VERSION ""

NS_ :

BS_:

BU_: Vector__XXX

BA_DEF_ BO_  "VFrameFormat" ENUM  "StandardCAN","ExtendedCAN";
BA_DEF_DEF_ "VFrameFormat" "StandardCAN";

CM_ "Ioniq 6 frame ids. The CCU CAN hub, which replaced the older ICU CAN hub, re-addresses classic 11-bit car-bus frames onto 29-bit extended ids that encode the original 11-bit id. This predates ccNC head units and is NOT a ccNC feature:";
CM_ "    prefix = 4 * (base >> 4)";
CM_ "    ext    = (prefix << 20) | (base << 8) | index        (id11 = base + index)";
CM_ "base = min(11-bit id of the family) - 1 and index = 1..N inside the family. Decode with base = (ext >> 8) & 0xFFF, index = ext & 0xFF, id11 = base + index.";
CM_ "This file uses BO_ = 0x80000000 | ext for the extended frames, plus BA_ \"VFrameFormat\" BO_ <id> 1 (ExtendedCAN). Worked example: 0x2AD -> base 0x2AA, index 3 -> 0x0A82AA03 -> BO_ 2323819011.";
CM_ "The remap is PARTIAL. Frames that keep their 11-bit id on Ioniq 6 include 0x448 (car bus) and the head-unit set 0x0C7 / 0x4CC / 0x4E8 / 0x4ED / 0x651 / 0x652. The 11-bit BO_ 56 (0x038) and BO_ 685 (0x2AD) definitions were REMOVED in Oct 2026: neither id is transmitted by the Ioniq 6 (0 frames in all five captures on disk, M-CAN), while the remapped 0x00C03503 and 0x0A82AA03 fire 7638 and 1910 times, so the 11-bit entries were unreachable and contradicted the CM_ of the frames themselves. The 11-bit BO_ 338 (0x152) is kept - that id does sometimes appear.";
CM_ "Verified byte-for-byte against Ioniq 5 / EV6 logs: 0x037 -> 0x00C03502, 0x038 -> 0x00C03503, 0x0A2 -> 0x0280A002, 0x10C -> 0x04010A02, 0x2AC/0x2AD/0x2AE -> 0x0A82AA02/03/04, 0x2E2/0x2E3/0x2E4 -> 0x0B82E002/03/04, 0x397/0x398 -> 0x0E439502/03.";
CM_ "RESOLVED Oct 2026: the CCU-hub form of 0x152 / BMS_10_100ms_2 IS transmitted. The whole family base 0x150 appears in the Ioniq 6 capture 'Battery conditioning test.csv' as 0x05415001/02/03/04 (index 1..4 -> 0x151..0x154 = BMS_10_100ms_1..4) at a steady 1.66 Hz with no gap longer than 0.3 s, so 0x152 -> BO_ 2235650050 (0x05415002). The earlier 'no base-0x150 frame is transmitted' finding came from an awake-not-READY capture (Ioniq6_off.csv, 44 extended ids); the new capture adds 192 extended ids in 71 families and every one still satisfies prefix == 4*(base>>4) with family indices contiguous from 1.";
CM_ "RESOLVED Oct 2026: 0x2FC / Battery_Info (state of charge) is BO_ 2344811010 (0x0BC2FA02, family base 0x2FA, index 2 -> 0x2FC). Byte 7 * 0.5 = SOC: 0xC6 = 198 = 99.0 % in 'Car off-ready-off-accessory.csv' / 'Car on steady state.csv' / 'Switching songs.csv', 0xC5 = 197 = 98.5 % in 'Battery conditioning test.csv'. Payload shape matches the Ioniq 5 0x2FC (byte 6 = 0x8F in both). NB: the 11-bit 0x2FB still appears on the Ioniq 6 bus but is a DIFFERENT frame (constant 00 04 61 F0 00 00 00 00); the real 0x2FB is the remap 0x0BC2FA01.";

BO_ 2160080131 Power_Status_Ioniq6: 8 Vector__XXX
	SG_ Power_Status_Ready : 0|4@1+ (1,0) [0|0] "" Vector__XXX

CM_ BO_ 2160080131 "POWER_STATUS for Ioniq 6: 29-bit 0x00C03503, the CCU-hub remap of 11-bit 0x038 (family 0x036-0x039, base 0x035, index 3). LS nibble of byte 0: 0x01 = awake but off, 0x04 = READY. Observed as 01 00 00 00 00 00 06 00 (awake, not READY) throughout an Ioniq 6 capture.";
CM_ SG_ 2160080131 Power_Status_Ready "LS nibble of byte 0";

VAL_ 2160080131 Power_Status_Ready 1 "Awake_Not_Ready" 4 "Ready" ;

BO_ 199 Toggle_Battery_Preconditioning: 8 Vector__XXX
	SG_ Battery_Preconditioning_0 : 24|8@1+ (1,0) [0|0] "" Vector__XXX
	SG_ Battery_Preconditioning_1 : 32|8@1+ (1,0) [0|0] "" Vector__XXX

CM_ BO_ 199 "Low level BMU control (preconditioning, utility mode activation; involved in start/stop). Head-unit bus frame, so the car-bus remap does not apply and the 11-bit id stands on Ioniq 6.";
CM_ SG_ 199 Battery_Preconditioning_0 "byte 3. Opcodes seen in the Ioniq 6 capture 'Car off-ready-off-accessory.csv' (12 frames): 0xE0 and 0xE1 (command trailers), plus the 0x00/0x40 forms in the CM_ of ioniq5-2022.dbc. This VAL_ only covers 0x00/0x40 - see the richer table in ioniq5-2022.dbc:158.";
CM_ SG_ 199 Battery_Preconditioning_1 "byte 4";

VAL_ 199 Battery_Preconditioning_0 0 "Off" 64 "On" ;
VAL_ 199 Battery_Preconditioning_1 0 "Off" 3 "On" ;

BO_ 2323819011 BMS_Precond_Status_Ioniq6: 8 Vector__XXX
	SG_ Battery_Precond_State : 8|8@1+ (1,0) [0|0] "" Vector__XXX

CM_ BO_ 2323819011 "BMS_Precond_Status for Ioniq 6 (extended ID 0x0A82AA03 = CCU-hub remap of 11-bit 0x2AD). Same byte-1 state semantics as 0x2AD on Ioniq 5 / EV6. Payload verified byte-for-byte against an Ioniq 5 capture: 00 01 00 40 FF FF FF 0F.";
CM_ SG_ 2323819011 Battery_Precond_State "byte 1 state";

VAL_ 2323819011 Battery_Precond_State 1 "Off" 5 "Preparing" 21 "On" ;

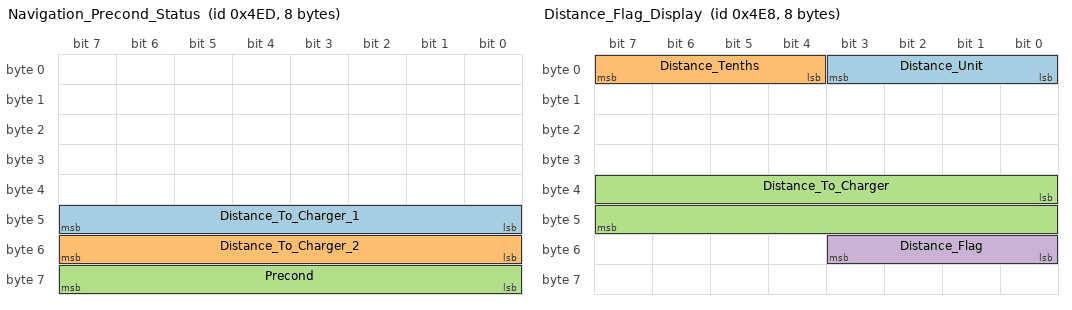
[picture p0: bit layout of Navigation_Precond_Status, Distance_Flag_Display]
BO_ 1261 Navigation_Precond_Status: 8 Vector__XXX
	SG_ Distance_To_Charger_1 : 40|8@1+ (1,0) [0|0] "" Vector__XXX
	SG_ Distance_To_Charger_2 : 48|8@1+ (1,0) [0|0] "" Vector__XXX
	SG_ Precond : 56|8@1+ (1,0) [0|0] "" Vector__XXX

CM_ BO_ 1261 "Navigation_Precond_Status (0x4ED): navigation distance to charger and precondition flag. Head-unit bus frame, kept 11-bit on Ioniq 6 (present in the Ioniq 6 capture as 00 00 00 00 00 FF FF 1F).";
CM_ SG_ 1261 Distance_To_Charger_1 "byte 5";
CM_ SG_ 1261 Distance_To_Charger_2 "byte 6";
CM_ SG_ 1261 Precond "byte 7";

BO_ 1256 Distance_Flag_Display: 8 Vector__XXX
	SG_ Distance_Unit : 0|4@1+ (1,0) [0|0] "" Vector__XXX
	SG_ Distance_Tenths : 4|4@1+ (1,0) [0|0] "" Vector__XXX
	SG_ Distance_To_Charger : 32|16@1+ (1,0) [0|0] "" Vector__XXX
	SG_ Distance_Flag : 48|4@1+ (1,0) [0|0] "" Vector__XXX

CM_ BO_ 1256 "Distance/flag display (0x4E8): byte0 = tenths<<4 | unit; bytes 4-5 = uint16 distance (LE); byte 6 LS nibble = flag. 0xFFFF distance hides the number. Head-unit bus frame, kept 11-bit on Ioniq 6.";
CM_ SG_ 1256 Distance_Unit "byte 0 LS nibble";
CM_ SG_ 1256 Distance_Tenths "byte 0 MS nibble";
CM_ SG_ 1256 Distance_To_Charger "bytes 4-5, uint16 LE";
CM_ SG_ 1256 Distance_Flag "byte 6 LS nibble";

VAL_ 1256 Distance_Unit 0 "M" 1 "KM" 2 "MI" 3 "FT" 4 "YD" ;
VAL_ 1256 Distance_Flag 0 "Destination" 1 "Blue 1" 2 "Blue 2" 3 "Blue 3" 4 "Blue 4" 15 "None" ;

BO_ 1228 Precond_Countdown_Flag: 8 Vector__XXX
	SG_ Precond_Countdown : 0|8@1+ (1,0) [0|0] "" Vector__XXX

CM_ BO_ 1228 "Preconditioning countdown flag (0x4CC). Head-unit bus frame, kept 11-bit on Ioniq 6 (present in the Ioniq 6 capture as 08 00 00 24 00 00 03 00).";
CM_ SG_ 1228 Precond_Countdown "byte 0";

BO_ 338 Battery_Temperature: 8 Vector__XXX
	SG_ Battery_Temperature_Min : 0|8@1- (1,0) [0|0] "" Vector__XXX
	SG_ Battery_Temperature_Max : 8|8@1- (1,0) [0|0] "" Vector__XXX

CM_ BO_ 338 "Battery temperature (0x152), Ioniq 5 / EV6 form: data[0] = min cell temp, data[1] = max cell temp (int8, deg C); data[2] carries a third cell temperature. On Ioniq 6 the frame is the 29-bit 0x05415002 = BO_ 2235650050.";
CM_ SG_ 338 Battery_Temperature_Min "byte 0, signed deg C";
CM_ SG_ 338 Battery_Temperature_Max "byte 1, signed deg C";

BO_ 2235650050 Battery_Temperature_Ioniq6: 8 Vector__XXX
	SG_ Battery_Temperature_Min : 0|8@1- (1,0) [0|0] "" Vector__XXX
	SG_ Battery_Temperature_Max : 8|8@1- (1,0) [0|0] "" Vector__XXX

CM_ BO_ 2235650050 "Battery temperature for Ioniq 6: 29-bit 0x05415002, the CCU-hub remap of 11-bit 0x152 (family 0x151-0x154, base 0x150, index 2). data[0] = min cell temp, data[1] = max cell temp, data[2] = a third cell temperature that trails data[1] by one step (all int8 deg C). Broadcast continuously at 1.66 Hz in 'Battery conditioning test.csv': byte 0 stays 0x0E (14 C) while byte 1 steps 0x0E -> 0x0F -> 0x10 -> 0x11 (14 -> 17 C) at 147.5 / 228.5 / 292.7 s and byte 2 follows at 157.1 / 237.5 s. Read in Fahrenheit (14 C = 57.2 F, 16 C = 60.8 F, 17 C = 62.6 F) that is the driver's 57/57 -> 57/61, with the last 5 s of the log reaching 57/63. The same min/max pair is mirrored in 0x0CC33502 (11-bit 0x337) bytes 3/4, switching at 227.9 s and 292.7 s.";
CM_ SG_ 2235650050 Battery_Temperature_Min "byte 0, signed deg C";
CM_ SG_ 2235650050 Battery_Temperature_Max "byte 1, signed deg C";
CM_ "CAUTION: only bytes 0-2 of 0x05415002 match the Ioniq 5 0x152 layout. The tail differs (Ioniq 5 has a non-zero byte 4 and zero bytes 6/7; Ioniq 6 has 00 00 00 34 6C constant), so do not carry the Ioniq 5 tail semantics across.";

BO_ 2344811010 Battery_Info_Ioniq6: 8 Vector__XXX
	SG_ State_Of_Charge : 56|8@1+ (0.5,0) [0|100] "%" Vector__XXX

CM_ BO_ 2344811010 "Battery_Info for Ioniq 6: 29-bit 0x0BC2FA02, the CCU-hub remap of 11-bit 0x2FC (family 0x2FB-0x2FE, base 0x2FA, index 2), same frame as Ioniq 5 / EV6 BO_ 764. Byte 7 * 0.5 = state of charge: 0xC6 = 198 = 99.0 % in 'Car off-ready-off-accessory.csv' / 'Car on steady state.csv' / 'Switching songs.csv' and 0xC5 = 197 = 98.5 % in 'Battery conditioning test.csv'. Broadcast at 5 Hz. Payload shape matches the Ioniq 5 frame (byte 6 = 0x8F in both).";
CM_ SG_ 2344811010 State_Of_Charge "byte 7, factor 0.5";

BO_ 2302827011 Charge_Limit_DC_Status_Ioniq6: 8 Vector__XXX
	SG_ DC_Charge_Limit : 8|8@1+ (0.5,0) [0|100] "%" Vector__XXX
	SG_ Conditioning_Mode_State : 40|8@1+ (1,0) [0|255] "" Vector__XXX

CM_ BO_ 2302827011 "DC charge limit + battery conditioning mode for Ioniq 6: 29-bit 0x09425A03, the CCU-hub remap of 11-bit 0x25D (BMS_04_100ms_3 in gen5w_hu_rx.dbc; Charge_Limit_DC_Status_25D in ioniq5-2022.dbc, BO_ 605). Family 0x25B-0x25E = BMS_04_100ms_1..4, base 0x25A, index 3 (prefix = 4*(0x25A>>4) = 0x094). Confirmed on the bus, not just derived: the whole family is transmitted on the CCU hub as 0x09425A01/02/03/04 -> 0x25B/0x25C/0x25D/0x25E, 744 frames each over 327.9 s in 'Battery conditioning test.csv'. NB the 0x25x block is split into per-group families: 0x09425001/02/03 -> 0x251/0x252/0x253 (base 0x250) and 0x09425501..04 -> 0x256..0x259 (base 0x255), so 0x25D is base 0x25A / index 3, NOT base 0x250 / index 0x0D.";
CM_ SG_ 2302827011 DC_Charge_Limit "byte 1, factor 0.5 -> percent; 0xA0 = 160 = 80 % in the conditioning capture (Ioniq 5 0x25D read 0xC8 = 100 %)";
CM_ SG_ 2302827011 Conditioning_Mode_State "byte 5: 0x80 = enabled, 0x40 = disabled. Only 0x80 was observed on Ioniq 6 - see the CAUTION below.";
CM_ "Observed shape for 0x09425A03: 00 A0 00 00 00 80 C0 71, with byte 2 constant 0x3A and byte 3 stepping 00/01/02 in the 00 A0 3A xx 00 80 C0 71 forms (744 frames over 327.9 s at a ~400 ms period: median 400.0 ms, p99 407.1 ms; that is 2.5 Hz, not the Ioniq 5 0x25D's 5 Hz). Bytes 2-3 and 7 differ from the Ioniq 5 frame (00 00 ... C0 70) and are undecoded - do not carry the Ioniq 5 tail semantics across.";
CM_ "CAUTION: only the enabled state (0x80) of Conditioning_Mode_State was observed on Ioniq 6; 'Battery conditioning test.csv' is a conditioning capture and the mode is on throughout. The 0x40 'Disabled' value in the VAL_ table is carried over from the Ioniq 5 0x25D table, not observed here.";

VAL_ 2302827011 Conditioning_Mode_State 128 "Enabled" 64 "Disabled" ;

BO_ 1096 Steering_Wheel_Buttons: 8 Vector__XXX
	SG_ Steering_Wheel_Other_Button : 16|8@1+ (1,0) [0|0] "" Vector__XXX
	SG_ Steering_Wheel_Star_Button : 40|8@1+ (1,0) [0|0] "" Vector__XXX

CM_ BO_ 1096 "Steering-wheel buttons (0x448): star, mode, speak, call, volume, skip, OK buttons. Car-bus frame that nevertheless KEEPS its 11-bit id on Ioniq 6 (present in the Ioniq 6 capture as 7F 00 00 00 00 00 00 00), so the CCU-hub remap is only partial.";
CM_ SG_ 1096 Steering_Wheel_Other_Button "byte 2";
CM_ SG_ 1096 Steering_Wheel_Star_Button "byte 5";

VAL_ 1096 Steering_Wheel_Other_Button 0 "None_Pressed" 1 "Speak_Pressed" 4 "Phone_Pressed" 64 "Mode_Pressed" ;
VAL_ 1096 Steering_Wheel_Star_Button 0 "Not_Pressed" 16 "Pressed" ;

BO_ 1617 AVN_Buttons_651: 8 Vector__XXX
	SG_ AVN_Vol_In : 12|4@1+ (1,0) [0|0] "" Vector__XXX
	SG_ AVN_Tuner_In : 28|4@1+ (1,0) [0|0] "" Vector__XXX

CM_ BO_ 1617 "AVN (head unit) button events (0x651); event frames sent only on press/release. VOL_IN = byte 1 MS nibble, TUNER_IN = byte 3 MS nibble. Head-unit bus frame, kept 11-bit on Ioniq 6.";
CM_ SG_ 1617 AVN_Vol_In "byte 1 MS nibble (mask 0xF0)";
CM_ SG_ 1617 AVN_Tuner_In "byte 3 MS nibble (mask 0xF0)";

VAL_ 1617 AVN_Vol_In 0 "Release" 3 "Release" 4 "Press" 7 "Press" ;
VAL_ 1617 AVN_Tuner_In 0 "Release" 3 "Release" 4 "Press" 7 "Press" ;

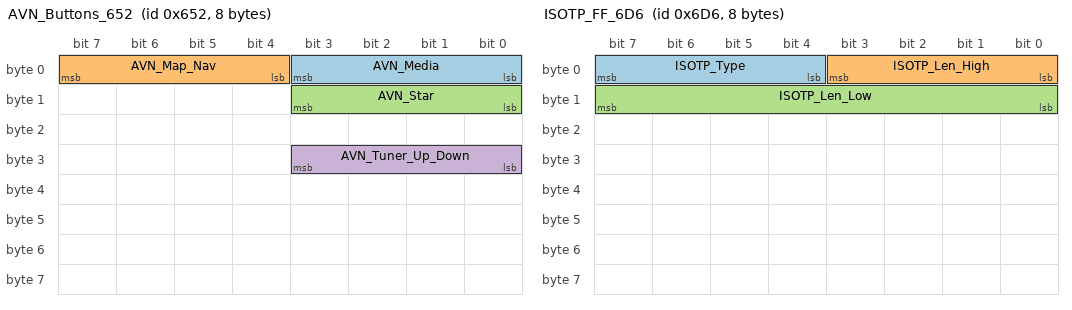
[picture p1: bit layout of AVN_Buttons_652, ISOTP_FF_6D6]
BO_ 1618 AVN_Buttons_652: 8 Vector__XXX
	SG_ AVN_Media : 0|4@1+ (1,0) [0|0] "" Vector__XXX
	SG_ AVN_Map_Nav : 4|4@1+ (1,0) [0|0] "" Vector__XXX
	SG_ AVN_Star : 8|4@1+ (1,0) [0|0] "" Vector__XXX
	SG_ AVN_Tuner_Up_Down : 24|4@1+ (1,0) [0|0] "" Vector__XXX

CM_ BO_ 1618 "AVN (head unit) button events (0x652). Per-byte nibble encoding: D1(byte0) MS=MAP/NAV LS=MEDIA; D2(byte1) LS=STAR; D4(byte3) LS=TUNER UP/DOWN. Seek/Call/Home/Mode signals are EV6-specific (see fluxer notes). Head-unit bus frame, kept 11-bit on Ioniq 6.";
CM_ SG_ 1618 AVN_Media "byte 0 LS nibble (mask 0x0F). 1=Media, 4=Radio (start radio, unconfirmed per fluxer notes)";
CM_ SG_ 1618 AVN_Map_Nav "byte 0 MS nibble (mask 0xF0). 1=Nav, 4=Map";
CM_ SG_ 1618 AVN_Star "byte 1 LS nibble (mask 0x0F). 4=Star";
CM_ SG_ 1618 AVN_Tuner_Up_Down "byte 3 LS nibble (mask 0x0F). 1=Down, 4=Up";

VAL_ 1618 AVN_Media 0 "Release" 1 "Press" 4 "Radio" 12 "Release" 13 "Press" ;
VAL_ 1618 AVN_Map_Nav 0 "Release" 1 "Nav Press" 3 "Release" 4 "Map Press" 7 "Map Press" 12 "Release" 13 "Nav Press" ;
VAL_ 1618 AVN_Star 0 "Release" 3 "Release" 4 "Press" 7 "Press" ;
VAL_ 1618 AVN_Tuner_Up_Down 0 "Release" 1 "Down Press" 3 "Release" 4 "Up Press" 7 "Up Press" 12 "Release" 13 "Down Press" ;

BO_ 1750 ISOTP_FF_6D6: 8 Vector__XXX
	SG_ ISOTP_Type : 4|4@1+ (1,0) [0|15] "" Vector__XXX
	SG_ ISOTP_Len_High : 0|4@1+ (1,0) [0|15] "" Vector__XXX
	SG_ ISOTP_Len_Low : 8|8@1+ (1,0) [0|255] "" Vector__XXX

CM_ BO_ 1750 "Track text, media ISO-TP first frame (0x6D6) -> flow control from 0x6B6 (BO_ 1718). Head-unit bus frame, kept 11-bit on Ioniq 6. The payload after the 2-byte ISO-TP header is bare UTF-16LE with NO SID/type byte, padded with 0xAA. VERIFIED on Ioniq 6: 'Switching songs.csv' carries a 36-byte transfer decoding to 'stream of silllver' and 'Battery conditioning test.csv' a 20-byte one decoding to 'Who's That'; both while 0x4CE byte 0 = 0xDC (Apple CarPlay). The same title is ALSO broadcast as a 128-byte message on 0x684 (duplicated on 0x686 about 250 ms later) as 10 80 followed by a one-byte type 0x6E ('n') then UTF-16LE; 0x684 is BO_ 1668 in ioniq5-2022.dbc (FC from 0x685) and no consecutive frames ever follow it in the Ioniq 6 captures.";
CM_ SG_ 1750 ISOTP_Type "1 = FirstFrame (2 = ConsecFrame on the same id)";
CM_ SG_ 1750 ISOTP_Len_High "high nibble of the 12-bit payload length";
CM_ SG_ 1750 ISOTP_Len_Low "low byte of the 12-bit payload length";

VAL_ 1750 ISOTP_Type 0 "SingleFrame" 1 "FirstFrame" 2 "ConsecFrame" 3 "FlowCtrl" ;

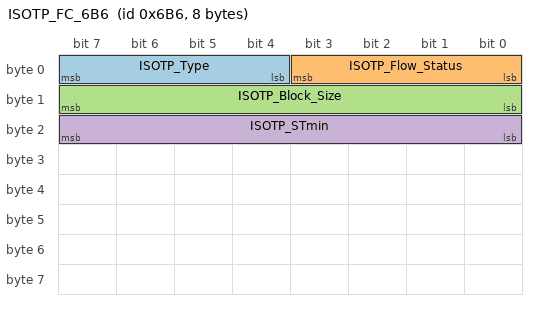
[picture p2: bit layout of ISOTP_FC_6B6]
BO_ 1718 ISOTP_FC_6B6: 8 Vector__XXX
	SG_ ISOTP_Type : 4|4@1+ (1,0) [0|15] "" Vector__XXX
	SG_ ISOTP_Flow_Status : 0|4@1+ (1,0) [0|15] "" Vector__XXX
	SG_ ISOTP_Block_Size : 8|8@1+ (1,0) [0|255] "" Vector__XXX
	SG_ ISOTP_STmin : 16|8@1+ (1,0) [0|255] "ms" Vector__XXX

CM_ BO_ 1718 "Track text flow control (0x6B6): the head unit answering a first frame on 0x6D6. Always 30 00 03 AA AA AA AA AA (CTS, block size 0, STmin 3 ms, padding 0xAA) in the Ioniq 6 captures.";
CM_ SG_ 1718 ISOTP_Block_Size "always 0 (send all remaining frames)";
CM_ SG_ 1718 ISOTP_STmin "3 ms";

VAL_ 1718 ISOTP_Type 0 "SingleFrame" 1 "FirstFrame" 2 "ConsecFrame" 3 "FlowCtrl" ;
VAL_ 1718 ISOTP_Flow_Status 0 "ContinueToSend" 1 "Wait" 2 "Overflow" ;

CM_ "Media ISO-TP, OPEN items on Ioniq 6. The other transports in wicant-i-precondition track_popup.c are not confirmed by these captures: 0x6E0 (Apps / Sounds of Nature) is NEVER transmitted in any Ioniq 6 log, and 0x6BE (its flow control) is transmitted exactly once - 30 00 03 AA AA AA AA AA at t=5.83 s in 'Battery conditioning test.csv', at a moment when 0x4CE byte 0 = 0x14 (media off), i.e. the fallback path that pins the media type to 0x04. An FC can only be sent by the receiver of a first frame, so the head unit does accept the 0x6E0/0x6BE pair, but no car-originated traffic exercises it: 0x4CE byte 0 is only ever 0x14 / 0xDC (CarPlay) / 0xDE (Android Auto) / 0xFE across the whole 45-log corpus, never 0x04 or 0x05. 0x4CE itself (media type + popup trigger) is still undocumented in these DBCs.";

BA_ "VFrameFormat" BO_ 2160080131 1;
BA_ "VFrameFormat" BO_ 2323819011 1;
BA_ "VFrameFormat" BO_ 2235650050 1;
BA_ "VFrameFormat" BO_ 2344811010 1;
BA_ "VFrameFormat" BO_ 2302827011 1;
